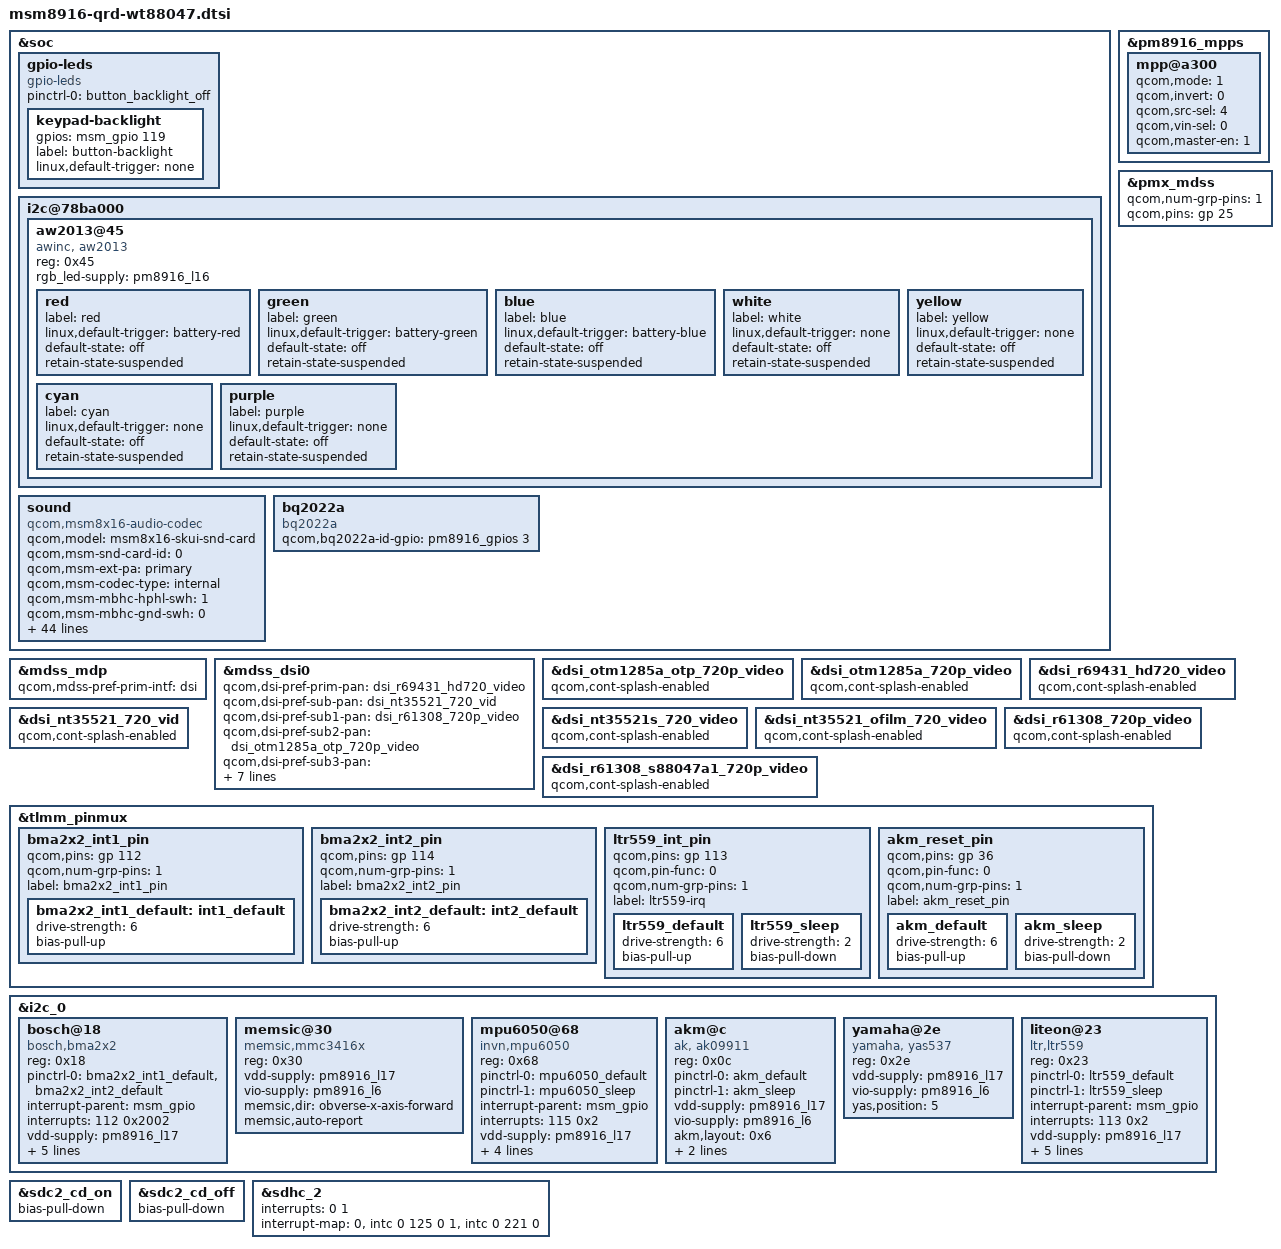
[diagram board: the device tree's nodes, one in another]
/* Copyright (c) 2014, The Linux Foundation. All rights reserved.
 * Copyright (C) 2016 XiaoMi, Inc.
 *
 * This program is free software; you can redistribute it and/or modify
 * it under the terms of the GNU General Public License version 2 and
 * only version 2 as published by the Free Software Foundation.
 *
 * This program is distributed in the hope that it will be useful,
 * but WITHOUT ANY WARRANTY; without even the implied warranty of
 * MERCHANTABILITY or FITNESS FOR A PARTICULAR PURPOSE.  See the
 * GNU General Public License for more details.
 */

#include "msm8916-qrd.dtsi"
#include "msm8916-camera-sensor-qrd-skui.dtsi"
#include "dsi-panel-r69431-hd720-video.dtsi"
#include "dsi-panel-nt35521-720p-video.dtsi"
#include "dsi-panel-nt35521s-720p-video.dtsi"
#include "dsi-panel-nt35521-ofilm-720p-video.dtsi"
#include "dsi-panel-otm1285a-720p-video.dtsi"
#include "dsi-panel-r61308-720p-video.dtsi"
#include "dsi-panel-otm1285a-otp-720p-video.dtsi"
#include "dsi-panel-r61308-s88047a1-720p-video.dtsi"

&soc {
	gpio-leds {
		compatible = "gpio-leds";
		status = "okay";
		pinctrl-names = "default";
		pinctrl-0 = <&button_backlight_off>;

		keypad-backlight {
			gpios = <&msm_gpio 119 0>;
			label = "button-backlight";
			linux,default-trigger = "none";
		};
	};
i2c@78ba000 {/* i2c 6 */
	aw2013@45 {/*blink */
		compatible = "awinc, aw2013";
		reg = <0x45>;
		rgb_led-supply = <&pm8916_l16>;

		red {
			label = "red";
			linux,default-trigger = "battery-red";
			default-state = "off";
			retain-state-suspended;
		};

		green {
			label = "green";
			linux,default-trigger = "battery-green";
			default-state = "off";
			retain-state-suspended;
		};

		blue {
			label = "blue";
			linux,default-trigger = "battery-blue";
			default-state = "off";
			retain-state-suspended;
		};
		white {
			label = "white";
			linux,default-trigger = "none";
			default-state = "off";
			retain-state-suspended;
		};

		yellow {
			label = "yellow";
			linux,default-trigger = "none";
			default-state = "off";
			retain-state-suspended;
		};

		cyan {
			label = "cyan";
			linux,default-trigger = "none";
			default-state = "off";
			retain-state-suspended;
		};
		purple {
			label = "purple";
			linux,default-trigger = "none";
			default-state = "off";
			retain-state-suspended;
		};

	};
};
	sound {
		compatible = "qcom,msm8x16-audio-codec";
		qcom,model = "msm8x16-skui-snd-card";
		qcom,msm-snd-card-id = <0>;
		qcom,msm-ext-pa = "primary";
		qcom,msm-codec-type = "internal";
		qcom,msm-mbhc-hphl-swh = <1>;
		qcom,msm-mbhc-gnd-swh = <0>;
		qcom,msm-hs-micbias-type = "internal";
		qcom,msm-micbias1-ext-cap;
		qcom,audio-routing =
			"RX_BIAS", "MCLK",
			"SPK_RX_BIAS", "MCLK",
			"INT_LDO_H", "MCLK",
			"MIC BIAS External", "Handset Mic",
			"MIC BIAS Internal2", "Headset Mic",
			"MIC BIAS External", "Secondary Mic",
			"AMIC1", "MIC BIAS External",
			"AMIC2", "MIC BIAS Internal2",
			"AMIC3", "MIC BIAS External";
		pinctrl-names = "cdc_lines_act",
				"cdc_lines_sus";
		pinctrl-0 = <&cdc_pdm_lines_act>;
		pinctrl-1 = <&cdc_pdm_lines_sus>;
		asoc-platform = <&pcm0>, <&pcm1>, <&voip>, <&voice>,
				<&loopback>, <&compress>, <&hostless>,
				<&afe>, <&lsm>, <&routing>, <&lpa>;
		asoc-platform-names = "msm-pcm-dsp.0", "msm-pcm-dsp.1",
				"msm-voip-dsp", "msm-pcm-voice", "msm-pcm-loopback",
				"msm-compress-dsp", "msm-pcm-hostless", "msm-pcm-afe",
				"msm-lsm-client", "msm-pcm-routing", "msm-pcm-lpa";
		asoc-cpu = <&dai_pri_auxpcm>, <&dai_hdmi>,
				<&dai_mi2s0>, <&dai_mi2s1>, <&dai_mi2s2>, <&dai_mi2s3>,
				<&sb_0_rx>, <&sb_0_tx>, <&sb_1_rx>, <&sb_1_tx>,
				<&sb_3_rx>, <&sb_3_tx>, <&sb_4_rx>, <&sb_4_tx>,
				<&bt_sco_rx>, <&bt_sco_tx>, <&int_fm_rx>, <&int_fm_tx>,
				<&afe_pcm_rx>, <&afe_pcm_tx>, <&afe_proxy_rx>, <&afe_proxy_tx>,
				<&incall_record_rx>, <&incall_record_tx>, <&incall_music_rx>,
				<&incall_music_2_rx>;
		asoc-cpu-names = "msm-dai-q6-auxpcm.1", "msm-dai-q6-hdmi.8",
				"msm-dai-q6-mi2s.0", "msm-dai-q6-mi2s.1",
				"msm-dai-q6-mi2s.2", "msm-dai-q6-mi2s.3",
				"msm-dai-q6-dev.16384", "msm-dai-q6-dev.16385",
				"msm-dai-q6-dev.16386", "msm-dai-q6-dev.16387",
				"msm-dai-q6-dev.16390", "msm-dai-q6-dev.16391",
				"msm-dai-q6-dev.16392", "msm-dai-q6-dev.16393",
				"msm-dai-q6-dev.12288", "msm-dai-q6-dev.12289",
				"msm-dai-q6-dev.12292", "msm-dai-q6-dev.12293",
				"msm-dai-q6-dev.224", "msm-dai-q6-dev.225",
				"msm-dai-q6-dev.241", "msm-dai-q6-dev.240",
				"msm-dai-q6-dev.32771", "msm-dai-q6-dev.32772",
				"msm-dai-q6-dev.32773", "msm-dai-q6-dev.32770";
		asoc-codec = <&stub_codec>, <&pm8916_tombak_dig>;
		asoc-codec-names = "msm-stub-codec.1", "tombak_codec";
	};
	bq2022a {
		compatible = "bq2022a";
		qcom,bq2022a-id-gpio = <&pm8916_gpios 3 0>;
		status= "okay";
	};
};

&pm8916_mpps {
	mpp@a300 {/* MPP 4 */
		/* Backlight PWM */
		qcom,mode = <1>;		/* Digital output */
		qcom,invert = <0>;		/* Disable invert */
		qcom,src-sel = <4>;		/* DTEST1 */
		qcom,vin-sel = <0>;		/* VPH_PWR */
		qcom,master-en = <1>;		/* Enable MPP */
	};
};

&mdss_mdp {
	qcom,mdss-pref-prim-intf = "dsi";
};

&pmx_mdss {
	qcom,num-grp-pins = <1>;
	qcom,pins = <&gp 25>;
};

&mdss_dsi0 {
	qcom,dsi-pref-prim-pan = <&dsi_r69431_hd720_video>;
	qcom,dsi-pref-sub-pan = <&dsi_nt35521_720_vid>;
	qcom,dsi-pref-sub1-pan = <&dsi_r61308_720p_video>;
	qcom,dsi-pref-sub2-pan = <&dsi_otm1285a_otp_720p_video>;
	qcom,dsi-pref-sub3-pan = <&dsi_r61308_s88047a1_720p_video>;
	qcom,dsi-pref-sub4-pan = <&dsi_nt35521s_720_video>;
	qcom,dsi-pref-sub5-pan = <&dsi_nt35521_ofilm_720_video>;
	pinctrl-names = "mdss_default", "mdss_sleep";
	pinctrl-0 = <&mdss_dsi_active>;
	pinctrl-1 = <&mdss_dsi_suspend>;

	qcom,platform-reset-gpio = <&msm_gpio 25 0>;
};

&dsi_otm1285a_otp_720p_video {
	qcom,cont-splash-enabled;
};

&dsi_otm1285a_720p_video {
	qcom,cont-splash-enabled;
};

&dsi_r69431_hd720_video {
	qcom,cont-splash-enabled;
};

&dsi_nt35521_720_vid {
	qcom,cont-splash-enabled;
};

&dsi_nt35521s_720_video {
	qcom,cont-splash-enabled;
};

&dsi_nt35521_ofilm_720_video {
	qcom,cont-splash-enabled;
};

&dsi_r61308_720p_video {
	qcom,cont-splash-enabled;
};

&dsi_r61308_s88047a1_720p_video {
	qcom,cont-splash-enabled;
};

&tlmm_pinmux {
	bma2x2_int1_pin {
		qcom,pins = <&gp 112>;
		qcom,num-grp-pins = <1>;
		label = "bma2x2_int1_pin";
		bma2x2_int1_default: int1_default {
			  drive-strength = <6>;
			  bias-pull-up;
		};
	};

	bma2x2_int2_pin {
		qcom,pins = <&gp 114>;
		qcom,num-grp-pins = <1>;
		label = "bma2x2_int2_pin";
		bma2x2_int2_default: int2_default {
			  drive-strength = <6>;
			  bias-pull-up;
		};
	};


	ltr559_int_pin {
		qcom,pins = <&gp 113>;
		qcom,pin-func = <0>;
		qcom,num-grp-pins = <1>;
		label = "ltr559-irq";
		ltr559_default: ltr559_default {
			drive-strength = <6>;
			bias-pull-up;
		};
		ltr559_sleep: ltr559_sleep {
			drive-strength = <2>;
			bias-pull-down;
		};
	};

	akm_reset_pin {
		qcom,pins = <&gp 36>;
		qcom,pin-func = <0>;
		qcom,num-grp-pins = <1>;
		label = "akm_reset_pin";
		akm_default: akm_default {
			drive-strength = <6>;
			bias-pull-up;
		};
		akm_sleep: akm_sleep {
			drive-strength = <2>;
			bias-pull-down;
		};
	};
};

&i2c_0 {/* BLSP1 QUP2 */
	/* Ambient light and proximity sensor */
	/*
	avago@39 {
		compatible = "avago,apds9930";
		reg = <0x39>;
		pinctrl-names = "default", "sleep";
		pinctrl-0 = <&apds99xx_default>;
		pinctrl-1 = <&apds99xx_sleep>;
		interrupt-parent = <&msm_gpio>;
		interrupts = <113 0x2002>;
		vdd-supply = <&pm8916_l17>;
		vio-supply = <&pm8916_l6>;
		avago,irq-gpio = <&msm_gpio 113 0x2002>;
		avago,ps-threshold = <600>;
		avago,ps-hysteresis-threshold = <500>;
		avago,ps-pulse = <8>;
		avago,ps-pgain = <0>;
		avago,als-B = <186>;
		avago,als-C = <75>;
		avago,als-D = <129>;
		avago,ga-value = <768>;
	};
	*/

	bosch@18 {/* Accelerometer sensor */
		compatible = "bosch,bma2x2";
		reg = <0x18>;
		pinctrl-names = "default";
		pinctrl-0 = <&bma2x2_int1_default &bma2x2_int2_default>;
		interrupt-parent = <&msm_gpio>;
		interrupts = <112 0x2002>;
		vdd-supply = <&pm8916_l17>;
		vio-supply = <&pm8916_l6>;
		bosch,init-interval = <200>;
		bosch,place = <2>;
		bosch,gpio-int1 = <&msm_gpio 112 0x2002>;
		bosch,gpio-int2 = <&msm_gpio 114 0x2002>;
	};

	memsic@30 {/* Magnetic field sensor */
		compatible = "memsic,mmc3416x";
		reg = <0x30>;
		vdd-supply = <&pm8916_l17>;
		vio-supply = <&pm8916_l6>;
		memsic,dir = "obverse-x-axis-forward";
		memsic,auto-report;
	};

	mpu6050@68 {
		compatible = "invn,mpu6050";
		reg = <0x68>;
		pinctrl-names = "mpu_default", "mpu_sleep";
		pinctrl-0 = <&mpu6050_default>;
		pinctrl-1 = <&mpu6050_sleep>;
		interrupt-parent = <&msm_gpio>;
		interrupts = <115 0x2>;
		vdd-supply = <&pm8916_l17>;
		vlogic-supply = <&pm8916_l16>;
		vi2c-supply = <&pm8916_l6>;
		invn,gpio-int = <&msm_gpio 115 0x2>;
		invn,place = "Portrait Up Back Side";
	};

	akm@c {
		compatible = "ak, ak09911";
		reg = <0x0c>;
		pinctrl-names = "default", "sleep";
		pinctrl-0 = <&akm_default>;
		pinctrl-1 = <&akm_sleep>;
		vdd-supply = <&pm8916_l17>;
		vio-supply = <&pm8916_l6>;
		akm,layout = <0x6>;
		akm,gpio_rstn = <&msm_gpio 36 0x0>;
		akm,auto-report;
	};

	yamaha@2e {/* Magnetic field sensor */
		compatible = "yamaha, yas537";
		reg = <0x2e>;
		vdd-supply = <&pm8916_l17>;
		vio-supply = <&pm8916_l6>;
		yas,position = <5>;
	};

	liteon@23 {
	  	compatible = "ltr,ltr559";
		reg = <0x23>;
		pinctrl-names = "default", "sleep";
		pinctrl-0 = <&ltr559_default>;
		pinctrl-1 = <&ltr559_sleep>;
		interrupt-parent = <&msm_gpio>;
		interrupts = <113 0x2>;
		vdd-supply = <&pm8916_l17>;
		vio-supply = <&pm8916_l6>;
		ltr,irq-gpio = <&msm_gpio 113 0x2>;
		ltr,ps-threshold = <45>;
		ltr,ps-hysteresis-threshold = <30>;
		ltr,als-polling-time = <200>;
	};

};

&sdc2_cd_on {
	/delete-property/ bias-pull-up;
	bias-pull-down;
};

&sdc2_cd_off {
	/delete-property/ bias-disable;
	bias-pull-down;
};

&sdhc_2 {
	interrupts = <0 1>;
	interrupt-map = <0 &intc 0 125 0
		1 &intc 0 221 0>;
	interrupt-names = "hc_irq", "pwr_irq";
	/delete-property/ cd-gpios;
};

